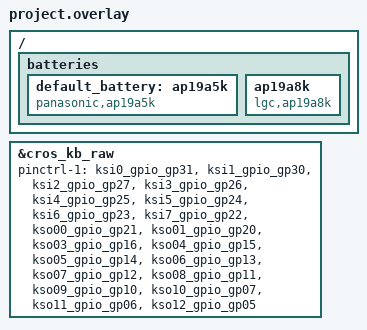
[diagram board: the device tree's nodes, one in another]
/* Copyright 2022 The ChromiumOS Authors
 * Use of this source code is governed by a BSD-style license that can be
 * found in the LICENSE file.
 */

/* Herobrine program common DTS includes */
#include "../adc.dtsi"
#include "../common.dtsi"
#include "../i2c.dtsi"
#include "../interrupts.dtsi"
#include "../keyboard.dtsi"
#include "../default_gpio_pinctrl.dtsi"
#include "../switchcap.dtsi"
#include "../usbc.dtsi"

/* Villager project DTS includes*/
#include "gpio.dtsi"
#include "led_pins.dtsi"
#include "led_policy.dtsi"
#include "motionsense.dtsi"

/* villager overrides follow... */
/* battery overrides */
/ {
	batteries {
		default_battery: ap19a5k {
			compatible = "panasonic,ap19a5k", "battery-smart";
		};
		ap19a8k {
			compatible = "lgc,ap19a8k", "battery-smart";
		};
	};
};

/* keyboard overrides */
&cros_kb_raw {
	status = "okay";
	pinctrl-1 = <
		&ksi0_gpio_gp31
		&ksi1_gpio_gp30
		&ksi2_gpio_gp27
		&ksi3_gpio_gp26
		&ksi4_gpio_gp25
		&ksi5_gpio_gp24
		&ksi6_gpio_gp23
		&ksi7_gpio_gp22
		&kso00_gpio_gp21
		&kso01_gpio_gp20
		&kso03_gpio_gp16
		&kso04_gpio_gp15
		&kso05_gpio_gp14
		&kso06_gpio_gp13
		&kso07_gpio_gp12
		&kso08_gpio_gp11
		&kso09_gpio_gp10
		&kso10_gpio_gp07
		&kso11_gpio_gp06
		&kso12_gpio_gp05
	>;
	pinctrl-names = "default", "sleep";
};
